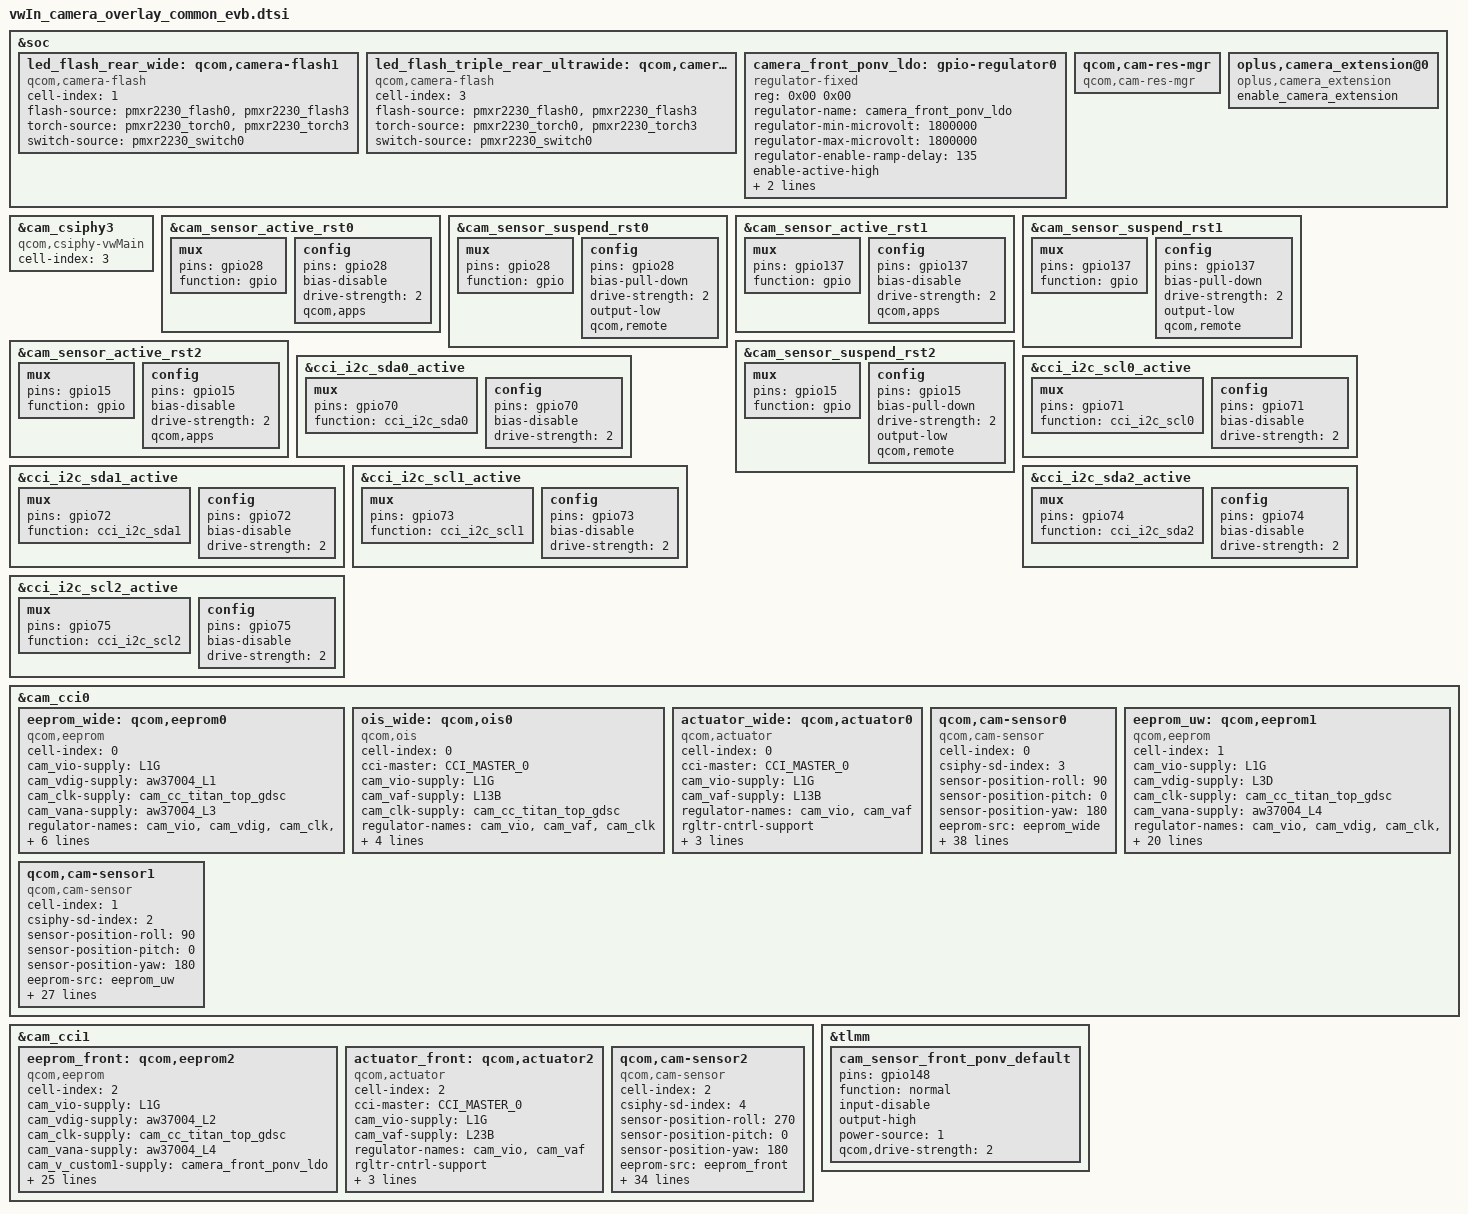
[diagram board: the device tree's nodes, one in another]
#include <dt-bindings/msm-camera.h>
#include "ftm_camera_settings.dtsi"
#include "regulator/aw37004.dtsi"

&soc {
	led_flash_rear_wide: qcom,camera-flash1 {
		cell-index = <1>;
		compatible = "qcom,camera-flash";
		flash-source = <&pmxr2230_flash0 &pmxr2230_flash3>;
		torch-source = <&pmxr2230_torch0 &pmxr2230_torch3>;
		switch-source = <&pmxr2230_switch0>;
		status = "ok";
	};

	led_flash_triple_rear_ultrawide: qcom,camera-flash3 {
		cell-index = <3>;
		compatible = "qcom,camera-flash";
		flash-source = <&pmxr2230_flash0 &pmxr2230_flash3>;
		torch-source = <&pmxr2230_torch0 &pmxr2230_torch3>;
		switch-source = <&pmxr2230_switch0>;
		status = "ok";
	};

	camera_front_ponv_ldo: gpio-regulator0 {
		compatible = "regulator-fixed";
		reg = <0x00 0x00>;
		regulator-name = "camera_front_ponv_ldo";
		regulator-min-microvolt = <1800000>;
		regulator-max-microvolt = <1800000>;
		regulator-enable-ramp-delay = <135>;
		enable-active-high;
		gpio = <&tlmm 148 0>;
		pinctrl-names = "default";
		pinctrl-0 = <&cam_sensor_front_ponv_default>;
	};

	qcom,cam-res-mgr {
		compatible = "qcom,cam-res-mgr";
		status = "ok";
	};

	oplus,camera_extension@0 {
		compatible = "oplus,camera_extension";
		enable_camera_extension;
		status = "ok";
	};

};

&cam_csiphy3{
	cell-index = <3>;
	compatible = "qcom,csiphy-vwMain", "qcom,csiphy";
};

&cam_sensor_active_rst0 {
	mux {
		pins = "gpio28";
		function = "gpio";
	};

	config {
		pins = "gpio28";
		bias-disable; /* No PULL */
		drive-strength = <2>; /* 2 MA */
		qcom,apps;
	};
};

&cam_sensor_suspend_rst0 {
	mux {
		pins = "gpio28";
		function = "gpio";
	};

	config {
		pins = "gpio28";
		bias-pull-down; /* PULL DOWN */
		drive-strength = <2>; /* 2 MA */
		output-low;
		qcom,remote;
	};
};

&cam_sensor_active_rst1 {
	mux {
		pins = "gpio137";
		function = "gpio";
	};

	config {
		pins = "gpio137";
		bias-disable; /* No PULL */
		drive-strength = <2>; /* 2 MA */
		qcom,apps;
	};
};

&cam_sensor_suspend_rst1 {
	mux {
		pins = "gpio137";
		function = "gpio";
	};

	config {
		pins = "gpio137";
		bias-pull-down; /* PULL DOWN */
		drive-strength = <2>; /* 2 MA */
		output-low;
		qcom,remote;
	};
};

&cam_sensor_active_rst2 {
	mux {
		pins = "gpio15";
		function = "gpio";
	};

	config {
		pins = "gpio15";
		bias-disable; /* No PULL */
		drive-strength = <2>; /* 2 MA */
		qcom,apps;
	};
};

&cam_sensor_suspend_rst2 {
	mux {
		pins = "gpio15";
		function = "gpio";
	};

	config {
		pins = "gpio15";
		bias-pull-down; /* PULL DOWN */
		drive-strength = <2>; /* 2 MA */
		output-low;
		qcom,remote;
	};
};

&cci_i2c_sda0_active {
	mux {
		/* CLK, DATA */
		pins = "gpio70";
		function = "cci_i2c_sda0";
	};

	config {
		pins = "gpio70";
		bias-disable; /* No PULL */
		drive-strength = <2>; /* 2 MA */
		//qcom,i2c_pull;
	};
};

&cci_i2c_scl0_active {
	mux {
		/* CLK, DATA */
		pins = "gpio71";
		function = "cci_i2c_scl0";
	};

	config {
		pins = "gpio71";
		bias-disable; /* No PULL */
		drive-strength = <2>; /* 2 MA */
		//qcom,i2c_pull;
	};
};

&cci_i2c_sda1_active {
	mux {
		/* CLK, DATA */
		pins = "gpio72";
		function = "cci_i2c_sda1";
	};

	config {
		pins = "gpio72";
		bias-disable; /* No PULL */
		drive-strength = <2>; /* 2 MA */
		//qcom,i2c_pull;
	};
};


&cci_i2c_scl1_active {
	mux {
		/* CLK, DATA */
		pins = "gpio73";
		function = "cci_i2c_scl1";
	};

	config {
		pins = "gpio73";
		bias-disable; /* No PULL */
		drive-strength = <2>; /* 2 MA */
		//qcom,i2c_pull;
	};
};

&cci_i2c_sda2_active {
	mux {
		/* CLK, DATA */
		pins = "gpio74";
		function = "cci_i2c_sda2";
	};

	config {
		pins = "gpio74";
		bias-disable; /* No PULL */
		drive-strength = <2>; /* 2 MA */
		//qcom,i2c_pull;
	};
};

&cci_i2c_scl2_active {
	mux {
		/* CLK, DATA */
		pins = "gpio75";
		function = "cci_i2c_scl2";
	};

	config {
		pins = "gpio75";
		bias-disable; /* No PULL */
		drive-strength = <2>; /* 2 MA */
		//qcom,i2c_pull;
	};
};

&cam_cci0 {

	eeprom_wide: qcom,eeprom0 {
		cell-index = <0>;
		//reg = <0x54>;
		compatible = "qcom,eeprom";
		cam_vio-supply = <&L1G>;
		cam_vdig-supply = <&aw37004_L1>;
		cam_clk-supply = <&cam_cc_titan_top_gdsc>;
		cam_vana-supply = <&aw37004_L3>;
		regulator-names = "cam_vio", "cam_vdig","cam_clk", "cam_vana";
		rgltr-cntrl-support;
		rgltr-min-voltage = <1800000 1100000 0 2800000>;
		rgltr-max-voltage = <1800000 1100000 0 2800000>;
		rgltr-load-current = <1200000 1200000 0 400000>;
		cci-master = <CCI_MASTER_0>;
		status = "ok";
	};

	ois_wide: qcom,ois0 {
		cell-index = <0>;
		compatible = "qcom,ois";
		cci-master = <CCI_MASTER_0>;
		cam_vio-supply = <&L1G>;
		cam_vaf-supply = <&L13B>;
		cam_clk-supply = <&cam_cc_titan_top_gdsc>;
		regulator-names = "cam_vio","cam_vaf", "cam_clk";
		rgltr-cntrl-support;
		rgltr-min-voltage = <1800000 2800000 0>;
		rgltr-max-voltage = <1800000 2800000 0>;
		rgltr-load-current = <1200000 1200000 0>;
		status = "ok";
	};

	actuator_wide: qcom,actuator0 {
		cell-index = <0>;
		compatible = "qcom,actuator";
		cci-master = <CCI_MASTER_0>;
		cam_vio-supply = <&L1G>;
		cam_vaf-supply = <&L13B>;
		regulator-names = "cam_vio", "cam_vaf";
		rgltr-cntrl-support;
		rgltr-min-voltage = <1800000 2800000>;
		rgltr-max-voltage = <1800000 2800000>;
		rgltr-load-current = <1200000 1200000>;
		status = "ok";
	};

	// wide camera
	qcom,cam-sensor0 {
		cell-index = <0>;
		compatible = "qcom,cam-sensor";
		csiphy-sd-index = <3>;
		sensor-position-roll = <90>;
		sensor-position-pitch = <0>;
		sensor-position-yaw = <180>;
		eeprom-src = <&eeprom_wide>;
		ois-src = <&ois_wide>;
		actuator-src = <&actuator_wide>;
		led-flash-src = <&led_flash_rear_wide>;
		cam_vio-supply = <&L1G>;
		cam_vdig-supply = <&aw37004_L1>;
		cam_clk-supply = <&cam_cc_titan_top_gdsc>;
		cam_vana-supply = <&aw37004_L3>;
		cam_vaf-supply = <&L13B>;
		//cam_v_custom1-supply = <&L3N>;
		regulator-names = "cam_vio", "cam_vdig", "cam_clk", "cam_vana",
			"cam_vaf";
		rgltr-cntrl-support;
		rgltr-min-voltage = <1800000 1100000 0 2800000 2800000>;
		rgltr-max-voltage = <1800000 1100000 0 2800000 2800000>;
		rgltr-load-current = <1200000 1200000 0 400000 1200000>;
		gpio-no-mux = <0>;
		pinctrl-names = "cam_default", "cam_suspend";
		pinctrl-0 = <&cam_sensor_mclk0_active
				&cam_sensor_active_rst0>;
		pinctrl-1 = <&cam_sensor_mclk0_suspend
				&cam_sensor_suspend_rst0>;
		gpios = <&tlmm 64 0>,
			<&tlmm 28 0>;
		gpio-reset = <1>;
		gpio-req-tbl-num = <0 1>;
		gpio-req-tbl-flags = <1 0>;
		gpio-req-tbl-label = "CAMIF_MCLK0",
					"CAM_RESET0";
		cci-master = <CCI_MASTER_0>;
		clocks = <&cambistmclkcc CAM_BIST_MCLK_CC_MCLK0_CLK>;
		clock-names = "cam_clk";
		clock-cntl-level = "nominal";
		clock-rates = <19200000>;
		//is-support-laser = <1>;
		enable_qsc_write_in_advance = <1>;
		qsc_reg_addr = <0x2210>;
		eeprom_slave_addr = <0xA0>;
		qsc_data_size = <3072>;
		write_qsc_addr = <0xC000>;
		ftm_setting_compatible = <'R' 0x0016 2 2 0x8202>; // expect camera_0016_8202
		status = "ok";
	};

	eeprom_uw: qcom,eeprom1 {
		cell-index = <1>;
		compatible = "qcom,eeprom";
		cam_vio-supply = <&L1G>;
		cam_vdig-supply = <&L3D>;
		cam_clk-supply = <&cam_cc_titan_top_gdsc>;
		cam_vana-supply = <&aw37004_L4>;
		regulator-names = "cam_vio", "cam_vdig","cam_clk", "cam_vana";
		rgltr-cntrl-support;
		rgltr-min-voltage = <1800000 1200000 0 2800000>;
		rgltr-max-voltage = <1800000 1200000 0 2800000>;
		rgltr-load-current = <1200000 1200000 0 400000>;
		gpio-no-mux = <0>;
		pinctrl-names = "cam_default", "cam_suspend";
		pinctrl-0 = <&cam_sensor_mclk1_active
				&cam_sensor_active_rst1>;
		pinctrl-1 = <&cam_sensor_mclk1_suspend
				&cam_sensor_suspend_rst1>;
		gpios = <&tlmm 65 0>,
			<&tlmm 137 0>;
		gpio-reset = <1>;
		gpio-req-tbl-num = <0 1>;
		gpio-req-tbl-flags = <1 0>;
		gpio-req-tbl-label = "CAMIF_MCLK1",
					"CAM_RESET1";
		cci-master = <CCI_MASTER_1>;
		clocks = <&cambistmclkcc CAM_BIST_MCLK_CC_MCLK1_CLK>;
		clock-names = "cam_clk";
		clock-cntl-level = "nominal";
		clock-rates = <19200000>;
		status = "ok";
	};

	// Ultra wide camera
	qcom,cam-sensor1 {
		cell-index = <1>;
		compatible = "qcom,cam-sensor";
		csiphy-sd-index = <2>;
		sensor-position-roll = <90>;
		sensor-position-pitch = <0>;
		sensor-position-yaw = <180>;
		eeprom-src = <&eeprom_uw>;
		//actuator-src = <&actuator_uw>;
		led-flash-src = <&led_flash_triple_rear_ultrawide>;
		cam_vio-supply = <&L1G>;
		cam_vdig-supply = <&L3D>;
		cam_clk-supply = <&cam_cc_titan_top_gdsc>;
		cam_vana-supply = <&aw37004_L4>;
		//cam_vaf-supply = <&L7M>;
		regulator-names = "cam_vio", "cam_vdig","cam_clk", "cam_vana";
		rgltr-cntrl-support;
		rgltr-min-voltage = <1800000 1200000 0 2800000>;
		rgltr-max-voltage = <1800000 1200000 0 2800000>;
		rgltr-load-current = <1200000 1200000 0 400000>;
		gpio-no-mux = <0>;
		pinctrl-names = "cam_default", "cam_suspend";
		pinctrl-0 = <&cam_sensor_mclk1_active
				&cam_sensor_active_rst1>;
		pinctrl-1 = <&cam_sensor_mclk1_suspend
				&cam_sensor_suspend_rst1>;
		gpios = <&tlmm 65 0>,
			<&tlmm 137 0>;
		gpio-reset = <1>;
		gpio-req-tbl-num = <0 1>;
		gpio-req-tbl-flags = <1 0>;
		gpio-req-tbl-label = "CAMIF_MCLK1",
					"CAM_RESET1";
		cci-master = <CCI_MASTER_1>;
		clocks = <&cambistmclkcc CAM_BIST_MCLK_CC_MCLK1_CLK>;
		clock-names = "cam_clk";
		clock-cntl-level = "nominal";
		clock-rates = <19200000>;
		ftm_setting_compatible = <'R' 0x0000 1 2 0x5608>; // expect camera_0000_5608
		status = "ok";
	};

};

&cam_cci1 {

	eeprom_front: qcom,eeprom2 {
		cell-index = <2>;
		compatible = "qcom,eeprom";
		cam_vio-supply = <&L1G>;
		cam_vdig-supply = <&aw37004_L2>;
		cam_clk-supply = <&cam_cc_titan_top_gdsc>;
		cam_vana-supply = <&aw37004_L4>;
		cam_v_custom1-supply = <&camera_front_ponv_ldo>;
		cam_v_custom2-supply = <&BOB1>;
		regulator-names = "cam_vio", "cam_vdig","cam_clk", "cam_vana", "cam_v_custom1", "cam_v_custom2";
		rgltr-cntrl-support;
		rgltr-min-voltage = <1800000 1100000 0 2800000 1800000 3008000>;
		rgltr-max-voltage = <1800000 1100000 0 2800000 1800000 4000000>;
		rgltr-load-current = <1200000 1200000 0 400000 400000 2000000>;
		gpio-no-mux = <0>;
		pinctrl-names = "cam_default", "cam_suspend";
		pinctrl-0 = <&cam_sensor_mclk4_active
				 &cam_sensor_active_rst2>;
		pinctrl-1 = <&cam_sensor_mclk4_suspend
				 &cam_sensor_suspend_rst2>;
		gpios = <&tlmm 68 0>,
			<&tlmm 15 0>;
		gpio-reset = <1>;
		gpio-req-tbl-num = <0 1>;
		gpio-req-tbl-flags = <1 0>;
		gpio-req-tbl-label = "CAMIF_MCLK4",
					"CAM_RESET2";
		cci-master = <CCI_MASTER_0>;
		clocks = <&cambistmclkcc CAM_BIST_MCLK_CC_MCLK4_CLK>;
		clock-names = "cam_clk";
		clock-cntl-level = "nominal";
		clock-rates = <19200000>;
		status = "ok";
	};

	actuator_front: qcom,actuator2 {
		cell-index = <2>;
		compatible = "qcom,actuator";
		cci-master = <CCI_MASTER_0>;
		cam_vio-supply = <&L1G>;
		cam_vaf-supply = <&L23B>;
		regulator-names = "cam_vio", "cam_vaf";
		rgltr-cntrl-support;
		rgltr-min-voltage = <1800000 2800000>;
		rgltr-max-voltage = <1800000 2800000>;
		rgltr-load-current = <1200000 150000>;
		status = "ok";
	};

	// front camera
	qcom,cam-sensor2 {
		cell-index = <2>;
		compatible = "qcom,cam-sensor";
		csiphy-sd-index = <4>;
		sensor-position-roll = <270>;
		sensor-position-pitch = <0>;
		sensor-position-yaw = <180>;
		eeprom-src = <&eeprom_front>;
		actuator-src = <&actuator_front>;
		cam_vio-supply = <&L1G>;
		cam_vdig-supply = <&aw37004_L2>;
		cam_clk-supply = <&cam_cc_titan_top_gdsc>;
		cam_vana-supply = <&aw37004_L4>;
		cam_vaf-supply = <&L23B>;
		cam_v_custom1-supply = <&camera_front_ponv_ldo>;
		cam_v_custom2-supply = <&BOB1>;
		regulator-names = "cam_vio", "cam_vdig","cam_clk", "cam_vana", "cam_vaf", "cam_v_custom1", "cam_v_custom2";
		rgltr-cntrl-support;
		//aon-camera-id = <AON_CAM1>;
		rgltr-min-voltage = <1800000 1100000 0 2800000 2800000 1800000 3008000>;
		rgltr-max-voltage = <1800000 1100000 0 2800000 2800000 1800000 4000000>;
		rgltr-load-current = <1200000 1200000 0 400000 150000 400000 2000000>;
		gpio-no-mux = <0>;
		pinctrl-names = "cam_default", "cam_suspend";
		pinctrl-0 = <&cam_sensor_mclk4_active
				 &cam_sensor_active_rst2>;
		pinctrl-1 = <&cam_sensor_mclk4_suspend
				 &cam_sensor_suspend_rst2>;
		gpios = <&tlmm 68 0>,
			<&tlmm 15 0>;
		gpio-reset = <1>;
		gpio-req-tbl-num = <0 1>;
		gpio-req-tbl-flags = <1 0>;
		gpio-req-tbl-label = "CAMIF_MCLK4",
					"CAM_RESET2";
		cci-master = <CCI_MASTER_0>;
		clocks = <&cambistmclkcc CAM_BIST_MCLK_CC_MCLK4_CLK>;
		clock-names = "cam_clk";
		clock-cntl-level = "nominal";
		clock-rates = <19200000>;
		ftm_setting_compatible = <'R' 0x03F0 2 2 0x32E2>; // expect camera_03F0_32E2
		status = "ok";
	};
};

&tlmm {
	cam_sensor_front_ponv_default: cam_sensor_front_ponv_default {
		/* PONV */
		pins = "gpio148";
		function = "normal";
		input-disable;
		output-high;
		power-source = <1>; /* 3.1V */
		qcom,drive-strength = <2>;
	};
};
